# NPCX490M register map
File version: 1.0
Registers are 8-bit, read-write, reset 0x0 unless marked. A register's access mark holds for its fields unless they carry their own. Offsets are from the block's base; [hi:lo] are bit positions; 'fields as' and 'values as' point back to an identical list.

## LFCG
Base 0x400B5100
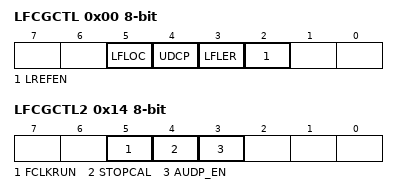
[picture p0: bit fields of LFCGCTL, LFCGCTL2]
0x00 LFCGCTL — LFCG Control Register (LFCGCTL)
  [5] LFLOC — LFCG Register Write Lock
  [4] UDCP — Update Calibration Parameters
  [3] LFLER — LFCG Locked on External Reference
  [2] LREFEN — LPC Clock Reference Enable
0x02 HFRDI 16-bit (reset mask 0xFF) — High-Frequency Reference Divisor I Register (HFRDI)
  [11:0] HFRDI — High-Frequency Reference Divisor I
0x04 HFRDF 16-bit (reset mask 0xFF) — High-Frequency Reference Divisor F Register (HFRDF)
0x06 FRCDIV 16-bit (reset mask 0xFF) — FRCLK Clock Divisor Register (FRCDIV)
  [8:0] FRCDIV — FRCLK Clock Divisor
0x08 DIVCOR1 16-bit (reset mask 0xFF) — Divisor Correction Value 1 Register (DIVCOR1)
  [8:0] DIVCOR1 — Divisor Correction Value 1
0x0A DIVCOR2 16-bit (reset mask 0xFF) — Divisor Correction Value 2 Register (DIVCOR2)
  [8:0] DIVCOR2 — Divisor Correction Value 2
0x14 LFCGCTL2 — LFCG Control 2 Register (LFCGCTL2)
  [5] FCLKRUN — Force PCI_CLK Running
  [4] STOPCAL — Stop Calibration to External Reference
  [3] AUDP_EN — Automatic Update Enable

## MDMA1
Base 0x40011100
Same registers: MDMA2 0x40011200, MDMA3 0x40011300, MDMA4 0x40011400, MDMA5 0x40011500, MDMA6 0x40011600, MDMA7 0x40011700
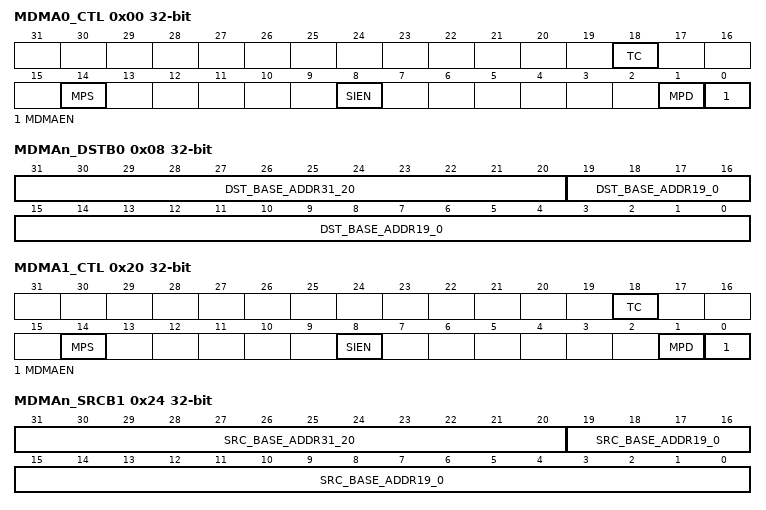
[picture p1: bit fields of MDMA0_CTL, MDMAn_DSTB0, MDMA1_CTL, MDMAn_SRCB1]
0x00 MDMA0_CTL 32-bit (reset mask 0xFF) — Channel 0/1 Control Register (MDMAn_CTL0, MDMAn_CTL1)
  [18] TC — Terminal Count
  [14] MPS — MDMA Power Save
  [8] SIEN — Stop Interrupt Enable
  [1] MPD — MDMA Power-Down
  [0] MDMAEN — MDMA Enable
0x04 MDMAn_SRCB0 32-bit (reset mask 0xFF) — Channel 0 Source Base Address Register (MDMAn_SRCB0)
0x08 MDMAn_DSTB0 32-bit (reset mask 0xFF) — Channel 0 Destination Base Address Register (MDMAn_DSTB0)
  [31:20] DST_BASE_ADDR31_20 — 32-bit Destination Base Address
  [19:0] DST_BASE_ADDR19_0 — 20-bit Destination Base Address
0x0C MDMA0_TCNT 32-bit (reset mask 0xFF) — Channel 0/1 Transfer Count Register (MDMAn_TCNT0, MDMAn_TCNT1)
  [12:0] TFR_CNT — 13-bit Transfer Count
0x14 MDMAn_CDST0 32-bit (reset mask 0xFF) — Channel 0 Current Destination Register (MDMAn_CDST0)
0x18 MDMA0_CTCNT 32-bit (reset mask 0xFF) — Channel 0/1 Current Transfer Count Register (MDMAn_CTCNT0, MDMAn_CTCNT1)
  [12:0] CURENT_TFR_CNT — 13-bit Current Transfer Count
0x20 MDMA1_CTL 32-bit (reset mask 0xFF) — Channel 0/1 Control Register (MDMAn_CTL0, MDMAn_CTL1)
  fields as MDMA0_CTL
0x24 MDMAn_SRCB1 32-bit (reset mask 0xFF) — Channel 1 Source Base Address Register (MDMAn_SRCB1)
  [31:20] SRC_BASE_ADDR31_20 — 12-bit Source Base Address
  [19:0] SRC_BASE_ADDR19_0 — 20-bit Source Base Address
0x28 MDMAn_DSTB1 32-bit (reset mask 0xFF) — Channel 1 Destination Base Address Register (MDMAn_DSTB1)
0x2C MDMA1_TCNT 32-bit (reset mask 0xFF) — Channel 0/1 Transfer Count Register (MDMAn_TCNT0, MDMAn_TCNT1)
  [12:0] TFR_CNT — 13-bit Transfer Count
0x30 MDMAn_CSRC1 32-bit (reset mask 0xFF) — Channel 1 Current Source Register (MDMAn_CSRC1)
0x38 MDMA1_CTCNT 32-bit (reset mask 0xFF) — Channel 0/1 Current Transfer Count Register (MDMAn_CTCNT0, MDMAn_CTCNT1)
  [12:0] CURENT_TFR_CNT — 13-bit Current Transfer Count

## MFT16_1
Base 0x400E1000
Same registers: MFT16_2 0x400E3000, MFT16_3 0x400E5000
0x00 TnCNT1 16-bit (reset mask 0xFF) — Timer/Counter 1 Register (TnCNT1)
0x02 TnCRA 16-bit (reset mask 0xFF) — Reload/Capture A Register (TnCRA)
0x04 TnCRB 16-bit (reset mask 0xFF) — Reload/Capture B Register (TnCRB)
0x06 TnCNT2 16-bit (reset mask 0xFF) — Timer/Counter 2 Register (TnCNT2)
0x08 TnPRSC — Clock Prescaler Register (TnPRSC)
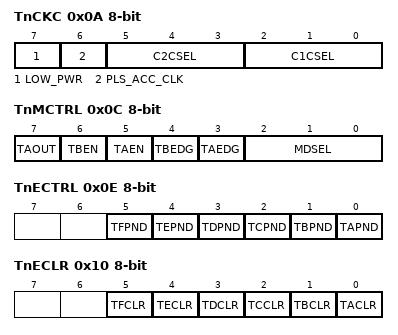
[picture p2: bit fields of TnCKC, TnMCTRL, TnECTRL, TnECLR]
0x0A TnCKC — Clock Unit Control Register (TnCKC)
  [7] LOW_PWR — Low-Power Mode Select
  [6] PLS_ACC_CLK — Pulse Accumulate Clock Select
  [5:3] C2CSEL — Counter 2 Clock Select
  [2:0] C1CSEL — Counter 1 Clock Select
0x0C TnMCTRL — Timer Mode Control Register (TnMCTRL)
  [7] TAOUT — TAn Output Data
  [6] TBEN — TBn Enable
  [5] TAEN — TAn Enable
  [4] TBEDG — TBn Edge Polarity
  [3] TAEDG — TAn Edge Polarity
  [2:0] MDSEL — Mode Select
0x0E TnECTRL — Timer Event Control Register (TnECTRL)
  [5] TFPND — Timer Event Source F Pending
  [4] TEPND — Timer Event Source E Pending
  [3] TDPND — Timer Event Source D Pending
  [2] TCPND — Timer Event Source C Pending
  [1] TBPND — Timer Event Source B Pending
  [0] TAPND — Timer Event Source A Pending
0x10 TnECLR — Timer Event Clear Register (TnECLR)
  [5] TFCLR — Timer Pending F Clear
  [4] TECLR — Timer Pending E Clear
  [3] TDCLR — Timer Pending D Clear
  [2] TCCLR — Timer Pending C Clear
  [1] TBCLR — Timer Pending B Clear
  [0] TACLR — Timer Pending A Clear
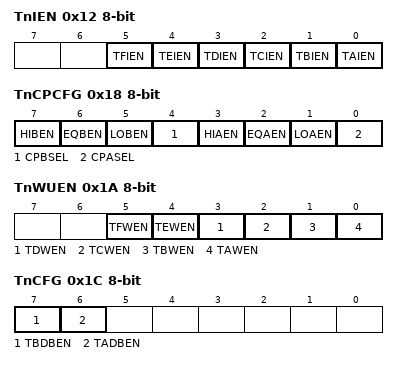
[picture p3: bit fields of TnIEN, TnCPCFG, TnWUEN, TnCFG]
0x12 TnIEN — Timer Interrupt Enable Register (TnIEN)
  [5] TFIEN — Timer Interrupt F Enable
  [4] TEIEN — Timer Interrupt E Enable
  [3] TDIEN — Timer Interrupt D Enable
  [2] TCIEN — Timer Interrupt C Enable
  [1] TBIEN — Timer Interrupt B Enable
  [0] TAIEN — Timer Interrupt A Enable
0x14 TnCPA 16-bit (reset mask 0xFF) — Compare A Register (TnCPA)
0x16 TnCPB 16-bit (reset mask 0xFF) — Compare B Register (TnCPB)
0x18 TnCPCFG — Compare Configuration Register (TnCPCFG)
  [7] HIBEN — High Indication Enable for Comparator B
  [6] EQBEN — Equal Indication Enable for Comparator B
  [5] LOBEN — Low Indication Enable for Comparator B
  [4] CPBSEL — Compare Function B Select
  [3] HIAEN — High Indication Enable for Comparator A
  [2] EQAEN — Equal Indication Enable for Comparator A
  [1] LOAEN — Low Indication Enable for Comparator A
  [0] CPASEL — Compare Function A Select
0x1A TnWUEN — Timer Wake-Up Enable Register (TnWUEN)
  [5] TFWEN — Timer Wake-Up F Enable
  [4] TEWEN — Timer Wake-Up E Enable
  [3] TDWEN — Timer Wake-Up D Enable
  [2] TCWEN — Timer Wake-Up C Enable
  [1] TBWEN — Timer Wake-Up B Enable
  [0] TAWEN — Timer Wake-Up A Enable
0x1C TnCFG — Timer Configuration Register (TnCFG)
  [7] TBDBEN — TBn Debounce Enable
  [6] TADBEN — TAn Debounce Enable
